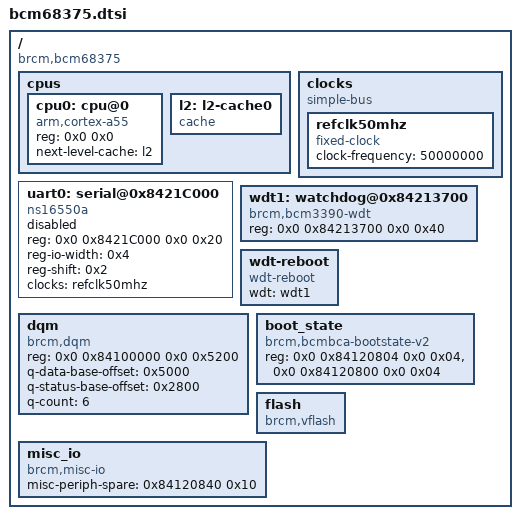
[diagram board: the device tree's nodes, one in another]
// SPDX-License-Identifier: GPL-2.0+
/*
 *  Copyright 2020 Broadcom Ltd.
 */

#include "skeleton64.dtsi"

/ {
	compatible = "brcm,bcm68375";
	#address-cells = <2>;
	#size-cells = <2>;

	cpus {
		#address-cells = <2>;
		#size-cells = <0>;

		cpu0: cpu@0 {
			compatible = "arm,cortex-a55", "arm,armv8";
			device_type = "cpu";
			reg = <0x0 0x0>;
			next-level-cache = <&l2>;
		};

		l2: l2-cache0 {
			compatible = "cache";
		};
	};

	clocks {
		compatible = "simple-bus";
		#address-cells = <2>;
		#size-cells = <2>;
		ranges;
		bootph-all;

		refclk50mhz: refclk50mhz {
			compatible = "fixed-clock";
			#clock-cells = <0>;
			clock-frequency = <50000000>;
			bootph-all;
		};
	};

	uart0: serial@0x8421C000 {
			compatible = "ns16550a";
			reg = <0x0 0x8421C000 0x0 0x20>;
			reg-io-width = <0x4>;
			reg-shift = <0x2>;
			clocks = <&refclk50mhz>;
			status = "disabled";
	};

	/* watchdog */
	wdt1: watchdog@0x84213700  {
		compatible = "brcm,bcm3390-wdt";
		reg = <0x0 0x84213700 0x0 0x40>;
		bootph-all;
	};

	wdt-reboot {
		compatible = "wdt-reboot";
		wdt = <&wdt1>;
	};

	dqm {
		compatible = "brcm,dqm";
		reg = <0x0 0x84100000 0x0 0x5200>;
		q-data-base-offset = <0x5000>;
		q-status-base-offset = <0x2800>;
		q-count         = <6>;
		bootph-all;
	};

	/* No Scratch in Pine XXX need Verify - Tomer */
	boot_state {
		bootph-all;
		compatible = "brcm,bcmbca-bootstate-v2";
		reg-names = "reset_reason", "reset_status";
		reg =  <0x0 0x84120804 0x0 0x04>,
			<0x0 0x84120800 0x0 0x04>;
	};

	flash {
		compatible = "brcm,vflash", "simple-bus";
		bootph-all;
	};

	misc_io {
		compatible = "brcm,misc-io";
		misc-periph-spare = <0x84120840 0x10>;
		bootph-all;
	};
};
